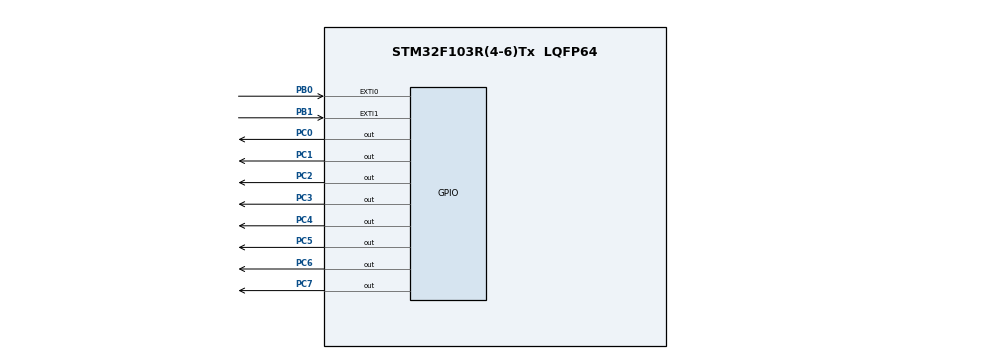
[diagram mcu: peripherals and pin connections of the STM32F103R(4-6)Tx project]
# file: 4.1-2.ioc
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Mcu.Family=STM32F1
Mcu.Name=STM32F103R(4-6)Tx
Mcu.Package=LQFP64
NVIC.EXTI0_IRQn=true\:2\:2\:true\:false\:true\:true\:true
NVIC.EXTI1_IRQn=true\:1\:1\:true\:false\:true\:true\:true
NVIC.PriorityGroup=NVIC_PRIORITYGROUP_2
PB0.GPIO_ModeDefaultEXTI=GPIO_MODE_IT_FALLING
PB0.Signal=GPXTI0
PB1.GPIO_ModeDefaultEXTI=GPIO_MODE_IT_FALLING
PB1.Signal=GPXTI1
PC0.PinState=GPIO_PIN_SET
PC0.Signal=GPIO_Output
PC1.PinState=GPIO_PIN_SET
PC1.Signal=GPIO_Output
PC2.PinState=GPIO_PIN_SET
PC2.Signal=GPIO_Output
PC3.PinState=GPIO_PIN_SET
PC3.Signal=GPIO_Output
PC4.PinState=GPIO_PIN_SET
PC4.Signal=GPIO_Output
PC5.PinState=GPIO_PIN_SET
PC5.Signal=GPIO_Output
PC6.PinState=GPIO_PIN_SET
PC6.Signal=GPIO_Output
PC7.PinState=GPIO_PIN_SET
PC7.Signal=GPIO_Output
ProjectManager.HeapSize=0x200
ProjectManager.StackSize=0x400
ProjectManager.TargetToolchain=STM32CubeIDE
RCC.APB1Freq_Value=8000000
RCC.APB2Freq_Value=8000000
VP_SYS_VS_ND.Mode=No_Debug
board=custom

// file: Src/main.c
/* USER CODE BEGIN Header */
/**
  ******************************************************************************
  * @file           : main.c
  * @brief          : Main program body
  ******************************************************************************
  * @attention
  *
  * <h2><center>&copy; Copyright (c) 2019 STMicroelectronics.
  * All rights reserved.</center></h2>
  *
  * This software component is licensed by ST under BSD 3-Clause license,
  * the "License"; You may not use this file except in compliance with the
  * License. You may obtain a copy of the License at:
  *                        opensource.org/licenses/BSD-3-Clause
  *
  ******************************************************************************
  */
/* USER CODE END Header */

#include "main.h"

void SystemClock_Config(void);
static void MX_GPIO_Init(void);

int main(void)
{
  /* USER CODE BEGIN 1 */
	int8_t i;
  /* USER CODE END 1 */

  /* MCU Configuration--------------------------------------------------------*/

  /* Reset of all peripherals, Initializes the Flash interface and the Systick. */
  HAL_Init();

  /* Configure the system clock */
  SystemClock_Config();

  /* Initialize all configured peripherals */
  MX_GPIO_Init();

  /* Infinite loop */
  /* USER CODE BEGIN WHILE */
  while (1)
  {
	  for(i=0;i<8;i++)
	  {
		  LL_GPIO_WriteOutputPort(GPIOC,(0xfe<<i)|(0xfe>>(8-i)));
		  HAL_Delay(500);
	  }
    /* USER CODE END WHILE */

  }
}

void SystemClock_Config(void)
{
  RCC_OscInitTypeDef RCC_OscInitStruct = {0};
  RCC_ClkInitTypeDef RCC_ClkInitStruct = {0};

  /** Initializes the CPU, AHB and APB busses clocks
  */
  RCC_OscInitStruct.OscillatorType = RCC_OSCILLATORTYPE_HSI;
  RCC_OscInitStruct.HSIState = RCC_HSI_ON;
  RCC_OscInitStruct.HSICalibrationValue = RCC_HSICALIBRATION_DEFAULT;
  RCC_OscInitStruct.PLL.PLLState = RCC_PLL_NONE;
  if (HAL_RCC_OscConfig(&RCC_OscInitStruct) != HAL_OK)
  {
    Error_Handler();
  }
  /** Initializes the CPU, AHB and APB busses clocks
  */
  RCC_ClkInitStruct.ClockType = RCC_CLOCKTYPE_HCLK|RCC_CLOCKTYPE_SYSCLK
                              |RCC_CLOCKTYPE_PCLK1|RCC_CLOCKTYPE_PCLK2;
  RCC_ClkInitStruct.SYSCLKSource = RCC_SYSCLKSOURCE_HSI;
  RCC_ClkInitStruct.AHBCLKDivider = RCC_SYSCLK_DIV1;
  RCC_ClkInitStruct.APB1CLKDivider = RCC_HCLK_DIV1;
  RCC_ClkInitStruct.APB2CLKDivider = RCC_HCLK_DIV1;

  if (HAL_RCC_ClockConfig(&RCC_ClkInitStruct, FLASH_LATENCY_0) != HAL_OK)
  {
    Error_Handler();
  }
}

static void MX_GPIO_Init(void)
{
  LL_EXTI_InitTypeDef EXTI_InitStruct = {0};
  LL_GPIO_InitTypeDef GPIO_InitStruct = {0};

  /* GPIO Ports Clock Enable */
  LL_APB2_GRP1_EnableClock(LL_APB2_GRP1_PERIPH_GPIOC);
  LL_APB2_GRP1_EnableClock(LL_APB2_GRP1_PERIPH_GPIOB);

  /**/
  LL_GPIO_SetOutputPin(GPIOC, LL_GPIO_PIN_0|LL_GPIO_PIN_1|LL_GPIO_PIN_2|LL_GPIO_PIN_3
                          |LL_GPIO_PIN_4|LL_GPIO_PIN_5|LL_GPIO_PIN_6|LL_GPIO_PIN_7);

  /**/
  GPIO_InitStruct.Pin = LL_GPIO_PIN_0|LL_GPIO_PIN_1|LL_GPIO_PIN_2|LL_GPIO_PIN_3
                          |LL_GPIO_PIN_4|LL_GPIO_PIN_5|LL_GPIO_PIN_6|LL_GPIO_PIN_7;
  GPIO_InitStruct.Mode = LL_GPIO_MODE_OUTPUT;
  GPIO_InitStruct.Speed = LL_GPIO_SPEED_FREQ_LOW;
  GPIO_InitStruct.OutputType = LL_GPIO_OUTPUT_PUSHPULL;
  LL_GPIO_Init(GPIOC, &GPIO_InitStruct);

  /**/
  LL_GPIO_AF_SetEXTISource(LL_GPIO_AF_EXTI_PORTB, LL_GPIO_AF_EXTI_LINE0);

  /**/
  LL_GPIO_AF_SetEXTISource(LL_GPIO_AF_EXTI_PORTB, LL_GPIO_AF_EXTI_LINE1);

  /**/
  EXTI_InitStruct.Line_0_31 = LL_EXTI_LINE_0;
  EXTI_InitStruct.LineCommand = ENABLE;
  EXTI_InitStruct.Mode = LL_EXTI_MODE_IT;
  EXTI_InitStruct.Trigger = LL_EXTI_TRIGGER_FALLING;
  LL_EXTI_Init(&EXTI_InitStruct);

  /**/
  EXTI_InitStruct.Line_0_31 = LL_EXTI_LINE_1;
  EXTI_InitStruct.LineCommand = ENABLE;
  EXTI_InitStruct.Mode = LL_EXTI_MODE_IT;
  EXTI_InitStruct.Trigger = LL_EXTI_TRIGGER_FALLING;
  LL_EXTI_Init(&EXTI_InitStruct);

  /**/
  LL_GPIO_SetPinMode(GPIOB, LL_GPIO_PIN_0, LL_GPIO_MODE_FLOATING);

  /**/
  LL_GPIO_SetPinMode(GPIOB, LL_GPIO_PIN_1, LL_GPIO_MODE_FLOATING);

  /* EXTI interrupt init*/
  NVIC_SetPriority(EXTI0_IRQn, NVIC_EncodePriority(NVIC_GetPriorityGrouping(),2, 2));
  NVIC_EnableIRQ(EXTI0_IRQn);
  NVIC_SetPriority(EXTI1_IRQn, NVIC_EncodePriority(NVIC_GetPriorityGrouping(),1, 1));
  NVIC_EnableIRQ(EXTI1_IRQn);

}

void Error_Handler(void)
{
}

/************************ (C) COPYRIGHT STMicroelectronics *****END OF FILE****/
